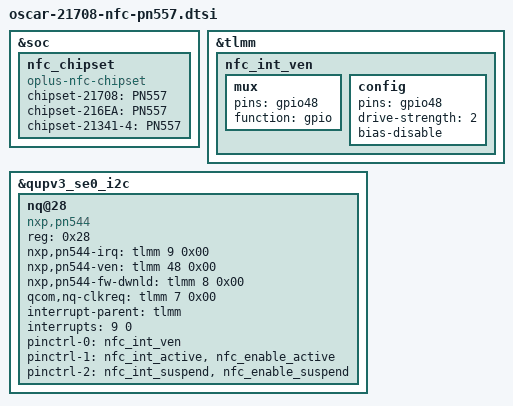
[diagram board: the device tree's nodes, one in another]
/**********************************************************************************
* Copyright (c)  2008-2020  Guangdong oplus Mobile Comm Corp., Ltd
* Description: oplus pn557 nfc dtsi
*
* Version: 1.0
* Date: 2020-10-02
* Author: ShiHao
*
* ------------------------------ Revision History: --------------------------------
* <version>           <date>                <author>                            <desc>
* Revision 1.0       2021-10-02              ShiHao           Created for Beta pn557 nfc dtsi
***********************************************************************************/
&soc {
	//add for nfc_chipset
	nfc_chipset {
        compatible = "oplus-nfc-chipset";
        chipset-21708 = "PN557";
        chipset-216EA = "PN557";
        chipset-21341-4 = "PN557";
	};
};

&tlmm {
    nfc_int_ven: nfc_int_ven {
	mux {
		pins = "gpio48";
		function = "gpio";
	};

	config {
		pins = "gpio48";
		drive-strength = <2>; /* 2 MA */
		bias-disable;
	};
    };
};


&qupv3_se0_i2c {
    //add for NXP PN557 NFC GPIO
	status = "ok";
	//qcom,clk-freq-out = <1000000>;
	#address-cells = <1>;
	#size-cells = <0>;
	nq@28 {
		compatible = "nxp,pn544";
		reg = <0x28>;
		nxp,pn544-irq = <&tlmm 9 0x00>;
		nxp,pn544-ven = <&tlmm 48 0x00>;
		nxp,pn544-fw-dwnld = <&tlmm 8 0x00>;
		qcom,nq-clkreq = <&tlmm 7 0x00>;
		interrupt-parent = <&tlmm>;
		interrupts = <9 0>;
		interrupt-names = "nfc_irq";
		pinctrl-names = "default","nfc_active", "nfc_suspend";
		pinctrl-0 = <&nfc_int_ven>;
		pinctrl-1 = <&nfc_int_active &nfc_enable_active>;
		pinctrl-2 = <&nfc_int_suspend &nfc_enable_suspend>;
	};
};
